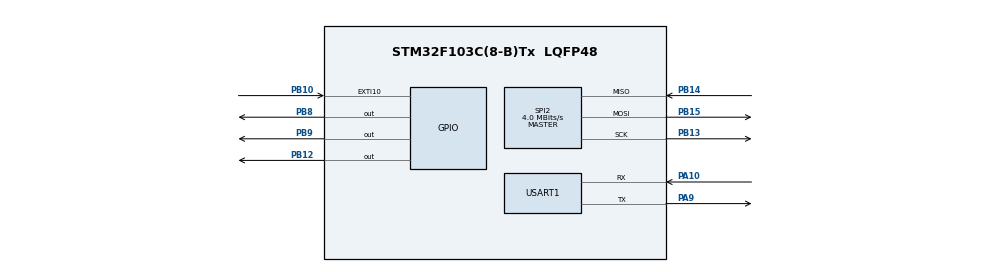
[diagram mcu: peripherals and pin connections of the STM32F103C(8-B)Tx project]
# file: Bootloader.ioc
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Mcu.Family=STM32F1
Mcu.Name=STM32F103C(8-B)Tx
Mcu.Package=LQFP48
NVIC.EXTI15_10_IRQn=true\:0\:0\:false\:false\:true\:true\:true\:true
NVIC.PriorityGroup=NVIC_PRIORITYGROUP_4
PA10.Mode=Asynchronous
PA10.Signal=USART1_RX
PA13.Mode=Serial_Wire
PA13.Signal=SYS_JTMS-SWDIO
PA14.Mode=Serial_Wire
PA14.Signal=SYS_JTCK-SWCLK
PA9.Mode=Asynchronous
PA9.Signal=USART1_TX
PB10.GPIO_ModeDefaultEXTI=GPIO_MODE_IT_FALLING
PB10.GPIO_PuPd=GPIO_PULLUP
PB10.Signal=GPXTI10
PB12.GPIO_Speed=GPIO_SPEED_FREQ_HIGH
PB12.PinState=GPIO_PIN_SET
PB12.Signal=GPIO_Output
PB13.Mode=Full_Duplex_Master
PB13.Signal=SPI2_SCK
PB14.Mode=Full_Duplex_Master
PB14.Signal=SPI2_MISO
PB15.Mode=Full_Duplex_Master
PB15.Signal=SPI2_MOSI
PB8.GPIO_ModeDefaultOutputPP=GPIO_MODE_OUTPUT_OD
PB8.GPIO_PuPd=GPIO_NOPULL
PB8.GPIO_Speed=GPIO_SPEED_FREQ_HIGH
PB8.PinState=GPIO_PIN_SET
PB8.Signal=GPIO_Output
PB9.GPIO_ModeDefaultOutputPP=GPIO_MODE_OUTPUT_OD
PB9.GPIO_PuPd=GPIO_NOPULL
PB9.GPIO_Speed=GPIO_SPEED_FREQ_HIGH
PB9.PinState=GPIO_PIN_SET
PB9.Signal=GPIO_Output
ProjectManager.HeapSize=0x200
ProjectManager.StackSize=0x400
ProjectManager.TargetToolchain=MDK-ARM V5.32
RCC.APB1Freq_Value=8000000
RCC.APB2Freq_Value=8000000
SPI2.CalculateBaudRate=4.0 MBits/s
SPI2.Direction=SPI_DIRECTION_2LINES
SPI2.Mode=SPI_MODE_MASTER
SPI2.VirtualType=VM_MASTER
TIM1.Prescaler=7
USART1.VirtualMode=VM_ASYNC
VP_TIM1_VS_ClockSourceINT.Mode=Internal
board=custom

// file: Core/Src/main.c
/* USER CODE BEGIN Header */
/**
  ******************************************************************************
  * @file           : main.c
  * @brief          : Main program body
  ******************************************************************************
  * @attention
  *
  * Copyright (c) 2026 STMicroelectronics.
  * All rights reserved.
  *
  * This software is licensed under terms that can be found in the LICENSE file
  * in the root directory of this software component.
  * If no LICENSE file comes with this software, it is provided AS-IS.
  *
  ******************************************************************************
  */
/* USER CODE END Header */
#include "main.h"

/* USER CODE BEGIN Includes */
#include "W25Q64.h"
#include <stdio.h>
#include "Bootloader.h"
#include "OLED.h"
#include "IR.h"
/* USER CODE END Includes */

SPI_HandleTypeDef hspi2;

TIM_HandleTypeDef htim1;

UART_HandleTypeDef huart1;

void SystemClock_Config(void);
static void MX_GPIO_Init(void);
static void MX_USART1_UART_Init(void);
static void MX_SPI2_Init(void);
static void MX_TIM1_Init(void);

int main(void)
{

  /* MCU Configuration--------------------------------------------------------*/

  /* Reset of all peripherals, Initializes the Flash interface and the Systick. */
  HAL_Init();

  /* Configure the system clock */
  SystemClock_Config();

  /* Initialize all configured peripherals */
  MX_GPIO_Init();
  MX_USART1_UART_Init();
  MX_SPI2_Init();
  MX_TIM1_Init();
  /* USER CODE BEGIN 2 */
	W25Q64_Init();
	IR_Init();
	OLED_Init();
	OLED_ShowString(1, 1, "hello world");
  /* USER CODE END 2 */

  /* Infinite loop */
  /* USER CODE BEGIN WHILE */

  while (1)
  {
    Bootloader_Run();
    /* USER CODE END WHILE */

  }
}

void SystemClock_Config(void)
{
  RCC_OscInitTypeDef RCC_OscInitStruct = {0};
  RCC_ClkInitTypeDef RCC_ClkInitStruct = {0};

  /** Initializes the RCC Oscillators according to the specified parameters
  * in the RCC_OscInitTypeDef structure.
  */
  RCC_OscInitStruct.OscillatorType = RCC_OSCILLATORTYPE_HSI;
  RCC_OscInitStruct.HSIState = RCC_HSI_ON;
  RCC_OscInitStruct.HSICalibrationValue = RCC_HSICALIBRATION_DEFAULT;
  RCC_OscInitStruct.PLL.PLLState = RCC_PLL_NONE;
  if (HAL_RCC_OscConfig(&RCC_OscInitStruct) != HAL_OK)
  {
    Error_Handler();
  }

  /** Initializes the CPU, AHB and APB buses clocks
  */
  RCC_ClkInitStruct.ClockType = RCC_CLOCKTYPE_HCLK|RCC_CLOCKTYPE_SYSCLK
                              |RCC_CLOCKTYPE_PCLK1|RCC_CLOCKTYPE_PCLK2;
  RCC_ClkInitStruct.SYSCLKSource = RCC_SYSCLKSOURCE_HSI;
  RCC_ClkInitStruct.AHBCLKDivider = RCC_SYSCLK_DIV1;
  RCC_ClkInitStruct.APB1CLKDivider = RCC_HCLK_DIV1;
  RCC_ClkInitStruct.APB2CLKDivider = RCC_HCLK_DIV1;

  if (HAL_RCC_ClockConfig(&RCC_ClkInitStruct, FLASH_LATENCY_0) != HAL_OK)
  {
    Error_Handler();
  }
}

static void MX_SPI2_Init(void)
{

  /* SPI2 parameter configuration*/
  hspi2.Instance = SPI2;
  hspi2.Init.Mode = SPI_MODE_MASTER;
  hspi2.Init.Direction = SPI_DIRECTION_2LINES;
  hspi2.Init.DataSize = SPI_DATASIZE_8BIT;
  hspi2.Init.CLKPolarity = SPI_POLARITY_LOW;
  hspi2.Init.CLKPhase = SPI_PHASE_1EDGE;
  hspi2.Init.NSS = SPI_NSS_SOFT;
  hspi2.Init.BaudRatePrescaler = SPI_BAUDRATEPRESCALER_2;
  hspi2.Init.FirstBit = SPI_FIRSTBIT_MSB;
  hspi2.Init.TIMode = SPI_TIMODE_DISABLE;
  hspi2.Init.CRCCalculation = SPI_CRCCALCULATION_DISABLE;
  hspi2.Init.CRCPolynomial = 10;
  if (HAL_SPI_Init(&hspi2) != HAL_OK)
  {
    Error_Handler();
  }

}

static void MX_TIM1_Init(void)
{

  TIM_ClockConfigTypeDef sClockSourceConfig = {0};
  TIM_MasterConfigTypeDef sMasterConfig = {0};

  htim1.Instance = TIM1;
  htim1.Init.Prescaler = 7;
  htim1.Init.CounterMode = TIM_COUNTERMODE_UP;
  htim1.Init.Period = 65535;
  htim1.Init.ClockDivision = TIM_CLOCKDIVISION_DIV1;
  htim1.Init.RepetitionCounter = 0;
  htim1.Init.AutoReloadPreload = TIM_AUTORELOAD_PRELOAD_DISABLE;
  if (HAL_TIM_Base_Init(&htim1) != HAL_OK)
  {
    Error_Handler();
  }
  sClockSourceConfig.ClockSource = TIM_CLOCKSOURCE_INTERNAL;
  if (HAL_TIM_ConfigClockSource(&htim1, &sClockSourceConfig) != HAL_OK)
  {
    Error_Handler();
  }
  sMasterConfig.MasterOutputTrigger = TIM_TRGO_RESET;
  sMasterConfig.MasterSlaveMode = TIM_MASTERSLAVEMODE_DISABLE;
  if (HAL_TIMEx_MasterConfigSynchronization(&htim1, &sMasterConfig) != HAL_OK)
  {
    Error_Handler();
  }

}

static void MX_USART1_UART_Init(void)
{

  huart1.Instance = USART1;
  huart1.Init.BaudRate = 115200;
  huart1.Init.WordLength = UART_WORDLENGTH_8B;
  huart1.Init.StopBits = UART_STOPBITS_1;
  huart1.Init.Parity = UART_PARITY_NONE;
  huart1.Init.Mode = UART_MODE_TX_RX;
  huart1.Init.HwFlowCtl = UART_HWCONTROL_NONE;
  huart1.Init.OverSampling = UART_OVERSAMPLING_16;
  if (HAL_UART_Init(&huart1) != HAL_OK)
  {
    Error_Handler();
  }

}

static void MX_GPIO_Init(void)
{
  GPIO_InitTypeDef GPIO_InitStruct = {0};

  /* GPIO Ports Clock Enable */
  __HAL_RCC_GPIOB_CLK_ENABLE();
  __HAL_RCC_GPIOA_CLK_ENABLE();

  /*Configure GPIO pin Output Level */
  HAL_GPIO_WritePin(GPIOB, GPIO_PIN_12|GPIO_PIN_8|GPIO_PIN_9, GPIO_PIN_SET);

  /*Configure GPIO pin : PB10 */
  GPIO_InitStruct.Pin = GPIO_PIN_10;
  GPIO_InitStruct.Mode = GPIO_MODE_IT_FALLING;
  GPIO_InitStruct.Pull = GPIO_PULLUP;
  HAL_GPIO_Init(GPIOB, &GPIO_InitStruct);

  /*Configure GPIO pin : PB12 */
  GPIO_InitStruct.Pin = GPIO_PIN_12;
  GPIO_InitStruct.Mode = GPIO_MODE_OUTPUT_PP;
  GPIO_InitStruct.Pull = GPIO_NOPULL;
  GPIO_InitStruct.Speed = GPIO_SPEED_FREQ_HIGH;
  HAL_GPIO_Init(GPIOB, &GPIO_InitStruct);

  /*Configure GPIO pins : PB8 PB9 */
  GPIO_InitStruct.Pin = GPIO_PIN_8|GPIO_PIN_9;
  GPIO_InitStruct.Mode = GPIO_MODE_OUTPUT_OD;
  GPIO_InitStruct.Pull = GPIO_NOPULL;
  GPIO_InitStruct.Speed = GPIO_SPEED_FREQ_HIGH;
  HAL_GPIO_Init(GPIOB, &GPIO_InitStruct);

  /* EXTI interrupt init*/
  HAL_NVIC_SetPriority(EXTI15_10_IRQn, 0, 0);
  HAL_NVIC_EnableIRQ(EXTI15_10_IRQn);

}

/* USER CODE BEGIN 4 */
int fputc(int ch, FILE *f)
{
	HAL_UART_Transmit(&huart1, (const uint8_t *)&ch, 1, HAL_MAX_DELAY);
	return ch;
}
/* USER CODE END 4 */

void Error_Handler(void)
{
  __disable_irq();
  while (1)
  {
  }
}
